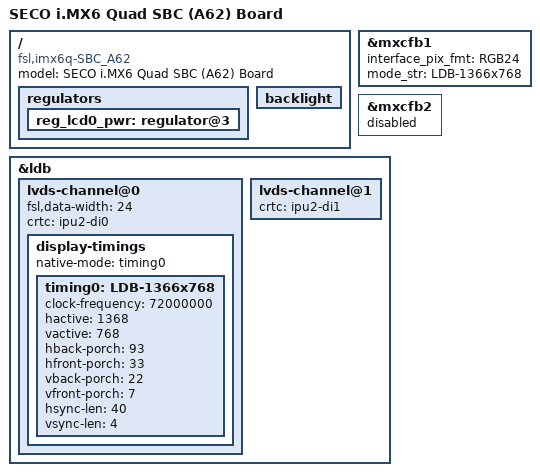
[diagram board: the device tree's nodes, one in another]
/*
 * Copyright 2013 Freescale Semiconductor, Inc.
 * Copyright 2015 Aidilab, Srl.
 *
 * The code contained herein is licensed under the GNU General Public
 * License. You may obtain a copy of the GNU General Public License
 * Version 2 or later at the following locations:
 *
 * http://www.opensource.org/licenses/gpl-license.html
 * http://www.gnu.org/copyleft/gpl.html
 */

/dts-v1/;

#include "imx6q.dtsi"
#include "imx6qdl-seco_A62.dtsi"

/ {
	model = "SECO i.MX6 Quad SBC (A62) Board";
	compatible = "fsl,imx6q-SBC_A62", "fsl,imx6q";

	regulators {
		reg_lcd0_pwr: regulator@3 {
			status = "okay";
		};
	};
	
	backlight {
		status = "okay";
	};
};

&mxcfb1 {
	interface_pix_fmt = "RGB24";
	mode_str ="LDB-1366x768";
	status = "okay";
};

&mxcfb2 {
	status = "disable";
};

&ldb {
	status = "okay";
	lvds-channel@0 {     
		status = "okay";
		fsl,data-width = <24>;
		crtc = "ipu2-di0";
		display-timings {
			native-mode = <&timing0>;
			timing0: LDB-1366x768 {
				clock-frequency = <72000000>;
				hactive = <1368>;
				vactive = <768>;
				hback-porch = <93>;
				hfront-porch = <33>;
				vback-porch = <22>;
				vfront-porch = <7>;
				hsync-len = <40>;
				vsync-len = <4>;
			};
		};
	};

	lvds-channel@1 {
		crtc = "ipu2-di1"; 
	};
};
